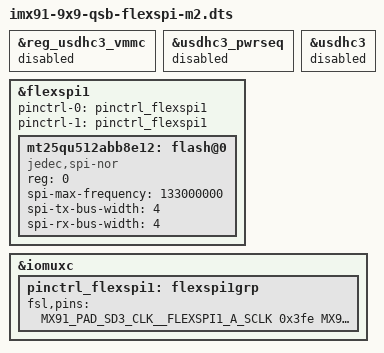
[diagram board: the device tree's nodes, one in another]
// SPDX-License-Identifier: (GPL-2.0+ OR MIT)
/*
 * Copyright 2024 NXP
 *
 */

#include "imx91-9x9-qsb-tianma-wvga-panel.dts"

&reg_usdhc3_vmmc {
	status = "disabled";
};

&usdhc3_pwrseq {
	status = "disabled";
};

&usdhc3 {
	status = "disabled";
};

&flexspi1 {
	pinctrl-names = "default", "sleep";
	pinctrl-0 = <&pinctrl_flexspi1>;
	pinctrl-1 = <&pinctrl_flexspi1>;
	status = "okay";

	mt25qu512abb8e12: flash@0 {
		reg = <0>;
		#address-cells = <1>;
		#size-cells = <1>;
		compatible = "jedec,spi-nor";
		spi-max-frequency = <133000000>;
		spi-tx-bus-width = <4>;
		spi-rx-bus-width = <4>;
	};
};

&iomuxc {
	pinctrl_flexspi1: flexspi1grp {
		fsl,pins = <
			MX91_PAD_SD3_CLK__FLEXSPI1_A_SCLK	0x3fe
			MX91_PAD_SD3_CMD__FLEXSPI1_A_SS0_B	0x3fe
			MX91_PAD_SD3_DATA0__FLEXSPI1_A_DATA0	0x3fe
			MX91_PAD_SD3_DATA1__FLEXSPI1_A_DATA1	0x3fe
			MX91_PAD_SD3_DATA2__FLEXSPI1_A_DATA2	0x3fe
			MX91_PAD_SD3_DATA3__FLEXSPI1_A_DATA3	0x3fe
		>;
	};
};
